# R7KA8T2AD register map
Vendor: Renesas Electronics Corporation; Series: RA8; File version: 1.10.02
CPU: CM85 r0p2, little endian, MPU, FPU, VTOR, 4 interrupt priority bits, 96 interrupts
Registers are 32-bit, read-write, reset 0x0 unless marked. A register's access mark holds for its fields unless they carry their own. Offsets are from the block's base; [hi:lo] are bit positions; {n}, {i} and the like mark numbered series; 'fields as' and 'values as' point back to an identical list.

## ESC — EtherCAT Slave Controller
Base 0x403A0000
0x00 TYPE 8-bit ro reset 0xA0
  [7:0] TYPE — Type of the EtherCAT slave controller
0x01 REVISION 8-bit ro reset 0x2
  [7:0] REV — Revision of the EtherCAT slave controller
0x02 BUILD 8-bit ro
  [7:0] BUILD — Build number of the EtherCAT slave controller
0x04 FMMU_NUM 8-bit ro reset 0x8 — FMMU Supported Register
  [7:0] NUMFMMU — Number of FMMU channels supported in the EtherCAT slave controller
0x05 SYNC_MANAGER 8-bit ro reset 0x8 — SyncManager Supported Register
  [7:0] NUMSYNC — Number of SyncManager channels supported in the EtherCAT slave controller
0x06 RAM_SIZE 8-bit ro reset 0x8
  [7:0] RAMSIZE — Process data RAM size supported in the EtherCAT slave controller (unit: KB)
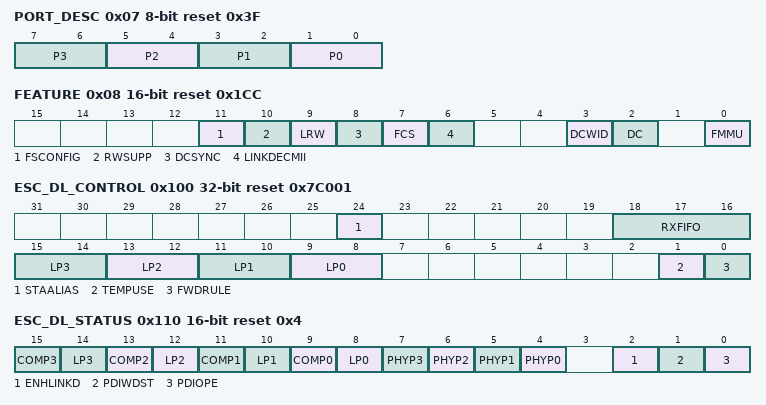
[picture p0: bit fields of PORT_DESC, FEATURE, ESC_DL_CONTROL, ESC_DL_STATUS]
0x07 PORT_DESC 8-bit ro reset 0x3F — Port Descriptor Register
  [all] fields
    0=Not implemented; 1=Not configured (SII EEPROM); 2=EBUS; 3=MII
  [2n+1:2n] P{n} (n=0..3) — Port {n} configuration
0x08 FEATURE 16-bit ro reset 0x1CC — ESC Features Supported Register
  [11] FSCONFIG — Fixed FMMU/SyncManager configuration
    0=Variable configuration; 1=Fixed configuration
  [10] RWSUPP — EtherCAT read/write command support (BRW, APRW, FPRW)
    0=Supported; 1=Not supported
  [9] LRW — EtherCAT LRW command support
    0=Supported; 1=Not supported
  [8] DCSYNC — Enhanced DC SYNC activation
    0=Not available; 1=Available
  [7] FCS — Separate handling of FCS errors
    0=Not supported; 1=Supported. Frames with wrong FCS and additional nibble will be counted separately in forwarded RX error counter.
  [6] LINKDECMII — Enhanced Link Detection in MII
    0=Not available; 1=Available
  [3] DCWID — Distributed Clock Width
    0=32 bits; 1=64 bits
  [2] DC — Distributed Clock
    0=Not available; 1=Available
  [0] FMMU — FMMU Operation
    0=Bit oriented; 1=Byte oriented
0x10 STATION_ADR 16-bit ro — Configured Station Address Register
  [15:0] NODADDR — Node Addressing Address Indication
0x12 STATION_ALIAS 16-bit — Configured Station Alias Register
  [15:0] NODALIADDR — Alias Address Indication
0x20 WR_REG_ENABLE 8-bit ro — Write Register Enable Register
  [0] ENABLE — Register Write Protection Unlock
0x21 WR_REG_PROTECT 8-bit ro — Write Register Protection Register
  [0] PROTECT — Register Write Protection Specification
    0=Protection disabled; 1=Protection enabled
0x30 ESC_WR_ENABLE 8-bit ro — ESC Write Enable Register
  [0] ENABLE — Register/Memory Write Protection Unlock
0x31 ESC_WR_PROTECT 8-bit ro — ESC Write Protection Register
  [0] PROTECT — Register/Memory Write Protection Specification
    0=Protection disabled; 1=Protection enabled
0x40 ESC_RESET_ECAT_R 8-bit ro — ESC Reset ECAT Register for read
  [1:0] RESET_ECAT — Reset Progress Status
    1=After writing 0x52; 2=After writing 0x45 (if 0x52 was written before); 0=Others
0x40 ESC_RESET_ECAT_W 8-bit ro (alternate view of ESC_RESET_ECAT_R) — ESC Reset ECAT Register for write
  [7:0] RESET_ECAT — Software Reset Setting
0x41 ESC_RESET_PDI_R 8-bit — ESC Reset PDI Register for read
  [1:0] RESET_PDI — Reset Progress Status
    values as ESC_RESET_ECAT_R.RESET_ECAT
0x41 ESC_RESET_PDI_W 8-bit (alternate view of ESC_RESET_PDI_R) — ESC Reset PDI Register for write
  [7:0] RESET_PDI — Software Reset Setting
0x100 ESC_DL_CONTROL ro reset 0x7C001
  [24] STAALIAS — Station Alias Status
    0=Ignore station alias; 1=Alias can be used for all configured address command types such as FPRD, FPWR
  [18:16] RXFIFO — RX FIFO Size
    0b00x=Shortened by 40 ns; 0b01x=Shortened by 40 ns; 6=No change; 7=Default; other=Others (No change)
  [2n+9:2n+8] LP{n} (n=0..3) — Loop Port {n} Configuration
    0=Auto; 1=Auto close; 2=Open; 3=Closed
  [1] TEMPUSE — Temporary Use of Bits 15 to 8 Settings
    0=Permanent use; 1=Use for about 1 second, then revert to previous settings
  [0] FWDRULE — Forwarding Rule
    0=EtherCAT frames are processed. Non-EtherCAT frames are forwarded without processing.; 1=EtherCAT frames are processed. Non-EtherCAT frames are destroyed.
0x108 PHYSICAL_RW_OFFSET 16-bit ro — Physical Read/Write Offset Register
  [15:0] RWOFFSET — Offset between Read and Write Addresses
0x110 ESC_DL_STATUS 16-bit ro reset 0x4
  [2n+9] COMP{n} (n=0..3) — Port {n} Communication State Indication
    0=No stable communication; 1=Communication established
  [2n+8] LP{n} (n=0..3) — Loop Port {n} State Indication
    0=Open; 1=Closed
  [n+4] PHYP{n} (n=0..3) — Port {n} Link State Indication
    0=No link; 1=Link detected
  [2] ENHLINKD — Enhanced Link Detection Indication
    0=Deactivated for all ports; 1=Activated for at least one port
  [1] PDIWDST — PDI Watchdog Timer Status
    0=Timeout of the watchdog timer; 1=Watchdog timer reloaded
  [0] PDIOPE — PDI/EEPROM Load State Indication
    0=EEPROM not loaded, the PDI not operational (process data RAM is not accessible); 1=EEPROM loaded correctly, the PDI operational (process data RAM is accessible)
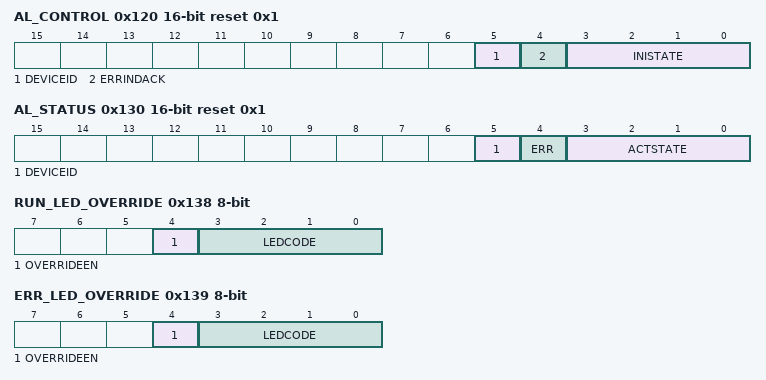
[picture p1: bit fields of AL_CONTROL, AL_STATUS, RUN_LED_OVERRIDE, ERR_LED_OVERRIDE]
0x120 AL_CONTROL 16-bit ro reset 0x1
  [5] DEVICEID — Device ID Request
    0=No request is present; 1=A request is present
  [4] ERRINDACK — Error Indication Acknowledge (Response)
    0=Error Indication in AL status register is not acknowledged; 1=Error Indication in AL status register is acknowledged
  [3:0] INISTATE — Change the state transition of the device state machine.
    1=Initial state request; 2=Pre-operational state request; 3=Bootstrap state request; 4=Safe-operational state request; 8=Operational state request; other=Others (Reserved)
0x130 AL_STATUS 16-bit reset 0x1
  [5] DEVICEID — Device ID Load State Indication
    0=Loading failed; 1=Loading was successful
  [4] ERR — Error State Indication
    0=The device is in the state as requested or flag was cleared by command; 1=The device has not entered the requested state or the state was changed as a result of local action
  [3:0] ACTSTATE — State Machine State Indication
    1=Initial state; 2=Pre-operational state; 3=Request bootstrap state; 4=Safe-operational state; 8=Operational state
0x134 AL_STATUS_CODE 16-bit
  [15:0] STATUSCODE — AL status code
0x138 RUN_LED_OVERRIDE 8-bit
  [4] OVERRIDEEN — Override Setting
    0=Override disabled; 1=Override enabled
  [3:0] LEDCODE — LED Code Indication (FSM state: Bits [3:0] of the AL Status register, AL_STATUS)
    0=Off (FSM: 1-Init); 13=Blinking (FSM: 2-PreOp); 14=Flickering (FSM: 3-Bootstrap); 15=On (FSM: 8-Op); other=Others (Flash 1x - 12x (FSM: 4-SafeOp 1x))
0x139 ERR_LED_OVERRIDE 8-bit
  [4] OVERRIDEEN — Override Setting
    0=Override disabled; 1=Override enabled
  [3:0] LEDCODE — LED Code Indication
    0=Off; 13=Blinking; 14=Flickering; 15=On; other=Others (Flash 1x to 12x)
0x140 PDI_CONTROL 8-bit ro reset 0x80
  [7:0] PDI — Process Data Interface. In this LSI, the following value is indicated.
    128=On-chip bus
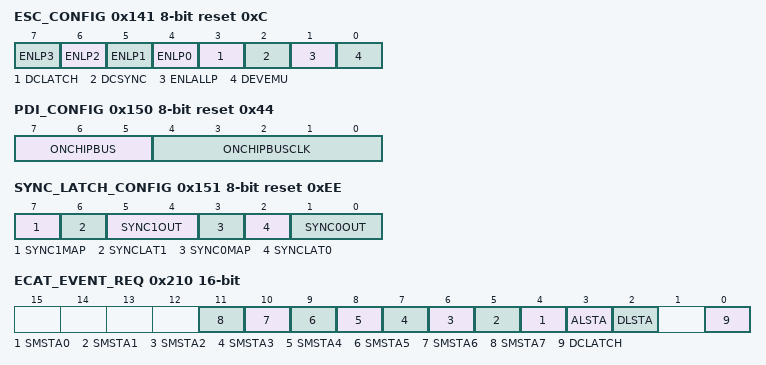
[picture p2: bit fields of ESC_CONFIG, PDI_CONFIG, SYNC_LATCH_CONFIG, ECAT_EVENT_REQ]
0x141 ESC_CONFIG 8-bit ro reset 0xC — ESC Configuration Register
  [n+4] ENLP{n} (n=0..3) — Port {n} Enhanced Link Detection Setting
    0=Disabled (if bit 9 of address 0 in the EEPROM = 0); 1=Enabled
  [3] DCLATCH — Sets the latch input unit for distributed clocks
    0=Disabled (power saving); 1=Enabled
  [2] DCSYNC — Sets the SYNC output unit for distributed clocks (fixed to 1 in this LSI)
    0=Disabled (power saving); 1=Enabled
  [1] ENLALLP — Sets enhanced link detection for all ports
    0=Disabled (if bits 15 to 12 of address 0 in the EEPROM = 0); 1=Enabled at all ports
  [0] DEVEMU — Device emulation (control of AL status)
    0=The AL status register must be set by the PDI; 1=The AL status register is set to a value written to the AL control register
0x150 PDI_CONFIG 8-bit ro reset 0x44 — PDI Configuration Register
  [7:5] ONCHIPBUS — On-Chip Bus Type Indication
  [4:0] ONCHIPBUSCLK — On-Chip Bus Clock Indication
0x151 SYNC_LATCH_CONFIG 8-bit ro reset 0xEE — SYNC/LATCH PDI Configuration Register
  [7] SYNC1MAP — SYNC1 State Mapping Indication
    0=Disabled; 1=Enabled
  [6] SYNCLAT1 — SYNC1/LATCH1 Indication
    0=LATCH1 input; 1=SYNC1 output
  [5:4] SYNC1OUT — SYNC1 Output Driver and Polarity Indication
  [3] SYNC0MAP — SYNC0 State Mapping Indication
    0=Disabled; 1=Enabled
  [2] SYNCLAT0 — SYNC0/LATCH0 Indication
    0=LATCH0 input; 1=SYNC0 output
  [1:0] SYNC0OUT — SYNC0 Output Driver and Polarity Indication
0x152 EXT_PDI_CONFIG 16-bit ro — Extended PDI Configuration Register
  [1:0] DATABUSWID — PDI Data Bus Width Indication
    0=4 bytes; 1=1 byte; 2=2 bytes
0x200 ECAT_EVENT_MASK 16-bit ro
  [15:0] ECATEVMASK — Event Request Mask Setting
    0=The corresponding bit of the ECAT Event Request register (ECAT_EVENT_REQ at 0x0210) is not mapped; 1=The corresponding bit of the ECAT Event Request register is mapped
0x204 AL_EVENT_MASK reset 0xFFFF0F
  [31:0] ALEVMASK — Event Request Mask Setting
    0=The corresponding bit of the AL Event Request register (AL_EVENT_REQ at 0x0220) is not mapped; 1=The corresponding bit of the AL Event Request register is mapped
0x210 ECAT_EVENT_REQ 16-bit ro — ECAT Event Request Register
  [n+4] SMSTA{n} (n=0..7) — Mirror value of SyncManager {n} Status Indication
    0=No Sync channel {n} event; 1=Sync channel {n} event pending
  [3] ALSTA — AL Status Event State Indication
    0=No change in AL status; 1=AL status change
  [2] DLSTA — DL Status Event State Indication
    0=No change in DL status; 1=DL status change
  [0] DCLATCH — DC Latch Event State Indication
    0=No change on DC latch inputs; 1=At least one change on DC latch inputs
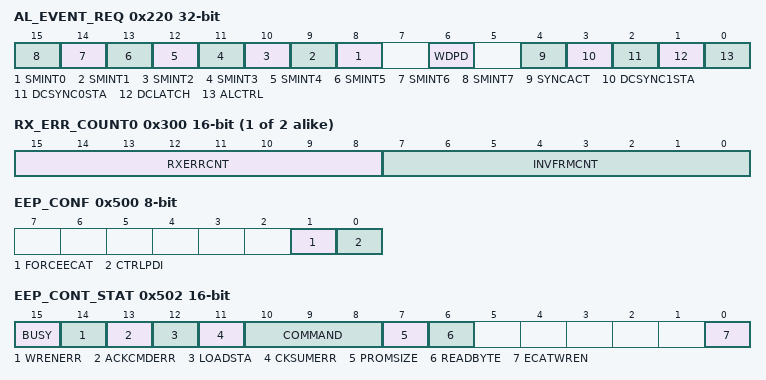
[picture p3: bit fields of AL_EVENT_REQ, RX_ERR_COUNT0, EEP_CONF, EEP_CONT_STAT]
0x220 AL_EVENT_REQ ro — AL Event Request Register
  [n+8] SMINT{n} (n=0..7) — SyncManager {n} interrupt (bit 0 or 1 of the SyncManager status register ({0x805+8n}))
    0=No SyncManager {n} interrupt; 1=SyncManager {n} interrupt pending
  [6] WDPD — Watchdog Process Data Indication
    0=Valid; 1=Timeout
  [4] SYNCACT — SyncManager Activation Indication
    0=No change in any SyncManager; 1=At least one SyncManager changed
  [3] DCSYNC1STA — DC SYNC1 State Indication
  [2] DCSYNC0STA — DC SYNC0 State Indication
  [1] DCLATCH — DC Latch Event State Indication
    values as ECAT_EVENT_REQ.DCLATCH
  [0] ALCTRL — AL Control Event State Indication
    0=No change in the AL control register; 1=The AL control register has been written
{0x300+2i} RX_ERR_COUNT{i} (i=0..1) 16-bit ro — RX Error Counter {i} Register (n = 0 to 1)
  [15:8] RXERRCNT — RX Frame Error Counter Value Indication
  [7:0] INVFRMCNT — Invalid Frame Counter Value Indication
{0x308+i} FWD_RX_ERR_COUNT{i} (i=0..1) 8-bit ro — Forwarded RX Error Counter {i} Register (n = 0 to 1)
  [7:0] FWDERRCNT — Forwarded Error Counter Value Indication
0x30C ECAT_PROC_ERR_COUNT 8-bit ro — ECAT Processing Unit Error Counter Register
  [7:0] EPUERRCNT — Processing Unit Error Counter Value Indication
0x30D PDI_ERR_COUNT 8-bit ro — PDI Error Counter Register
  [7:0] PDIERRCNT — PDI Error Counter Value Indication
{0x310+i} LOST_LINK_COUNT{i} (i=0..1) 8-bit ro — Lost Link Counter {i} Register (n = 0 to 1)
  [7:0] LOSTLINKCNT — Lost Link Counter Value Indication
0x400 WD_DIVIDE 16-bit ro reset 0x9C2 — Watchdog Divider Register
  [15:0] WDDIV — Watchdog Clock Frequency Divisor Setting
0x410 WDT_PDI 16-bit ro reset 0x3E8 — Watchdog Time PDI Register
  [15:0] WDTIMPDI — Watchdog Overflow Time Setting
0x420 WDT_DATA 16-bit ro reset 0x3E8 — Watchdog Time Process Data Register
  [15:0] WDTIMPD — Watchdog Overflow Time Setting
0x440 WDS_DATA 16-bit ro — Watchdog Status Process Data Register
  [0] WDSTAPD — Watchdog State Indication
    0=The timeout period of the process data watchdog timer elapses; 1=The process data watchdog timer is active or disabled
0x442 WDC_DATA 8-bit ro — Watchdog Counter Process Data Register
  [7:0] WDCNTPD — Watchdog Counter Value Indication
0x443 WDC_PDI 8-bit ro — Watchdog Counter PDI Register
  [7:0] WDCNTPDI — Watchdog Counter Value Indication
0x500 EEP_CONF 8-bit ro — EEPROM Configuration Register
  [1] FORCEECAT — EEPROM Access Right Change
    0=No change; 1=Reset bit 0 of the EEPROM PDI Access State register (EEP_STATE at 0x0501) to 0. That is, prohibit access to the EEPROM by the PDI.
  [0] CTRLPDI — PDI EEPROM Control
    0=The PDI has no EEPROM control; 1=The PDI has EEPROM control
0x501 EEP_STATE 8-bit — EEPROM PDI Access State Register
  [0] PDIACCESS — EEPROM Access Right Setting
    0=Prohibits the PDI from access to the EEPROM; 1=The PDI has access to the EEPROM
0x502 EEP_CONT_STAT 16-bit (reset mask 0xFF41) — EEPROM Control/Status Register
  [15] BUSY ro — EEPROM Interface State Indication
    0=The EEPROM interface is idle; 1=The EEPROM interface is busy
  [14] WRENERR ro — Write Enable Error Indication
    0=No error; 1=Write command without write enable
  [13] ACKCMDERR ro — Acknowledge/Command Error Indication
    0=No error; 1=Missing EEPROM acknowledge or invalid command
  [12] LOADSTA ro — EEPROM Loading Status Indication
    0=EEPROM has been loaded and device information has no problem; 1=EEPROM has not been loaded and device information is not available (EEPROM loading in progress or finished with a failure)
  [11] CKSUMERR ro — Checksum Error Indication
    0=No error in the checksum; 1=Error in the checksum
  [10:8] COMMAND
    0=No command/EEPROM idle (clear error bits); 1=Read; 2=Write; 4=Reload; other=Others (Reserved/invalid commands (must not be issued))
  [7] PROMSIZE ro — EEPROM Algorithm Indication
    0=1 address byte (1-Kbit to 16-Kbit EEPROMs); 1=2 address bytes (32-Kbit to 4-Mbit EEPROMs)
  [6] READBYTE ro — EEPROM Read Byte Indication
    0=4 bytes; 1=8 bytes
  [0] ECATWREN ro — ECAT Write Enable
    0=Write requests are disabled; 1=Write requests are enabled
0x504 EEP_ADR — EEPROM Address Register
  [31:0] ADDRESS — EEPROM Address Setting
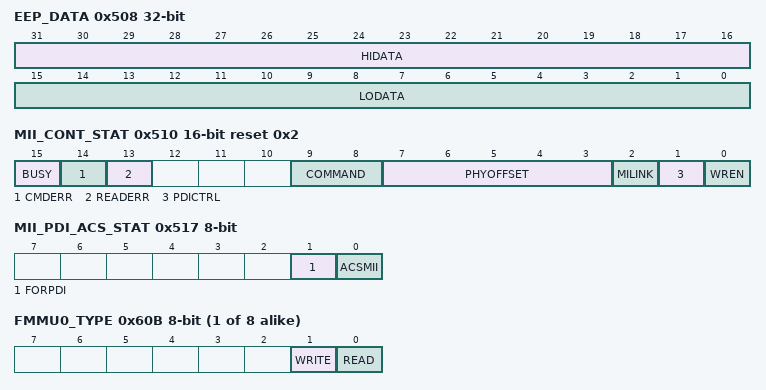
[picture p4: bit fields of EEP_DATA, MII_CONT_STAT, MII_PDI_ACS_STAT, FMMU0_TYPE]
0x508 EEP_DATA — EEPROM Data Register
  [31:16] HIDATA ro — Data read from the EEPROM (upper 2 bytes)
  [15:0] LODATA — Data to be written to the EEPROM or data read from the EEPROM (lower 2 bytes)
0x510 MII_CONT_STAT 16-bit reset 0x2 — MII Management Control/Status Register
  [15] BUSY ro — MII Management State Indication
    0=MII management interface is idle; 1=MII management interface is busy
  [14] CMDERR ro — Command Error Indication
    0=Last command was successful; 1=Invalid command or write command without write enable
  [13] READERR — Read Error Indication
    0=No read error; 1=Read error occurred (PHY or register not available)
  [9:8] COMMAND
    0=No command/MI idle (clear error bits); 1=Read; 2=Write; other=Others (Setting prohibited)
  [7:3] PHYOFFSET ro — PHY Address Offset Indication
  [2] MILINK ro — MI Link Detection
    0=Not available; 1=Available
  [1] PDICTRL ro — PDI Control Indication
    0=Only ECAT control; 1=PDI control possible
  [0] WREN ro — Write Enable
    0=Disabled; 1=Enabled
0x512 PHY_ADR 8-bit — PHY Address Register
  [4:0] PHYADDR — PHY Address Setting
0x513 PHY_REG_ADR 8-bit — PHY Register Address Register
  [4:0] PHYREGADDR — Address of PHY register
0x514 PHY_DATA 16-bit
  [15:0] PHYREGDATA — PHY Register Data Indication/Setting
0x516 MII_ECAT_ACS_STAT 8-bit ro — MII Management ECAT Access State Register
  [0] ACSMII — MII Management Interface Access Right Setting
    0=Enables access to the MII management interface by the PDI; 1=Exclusive access to the MII management interface by the ECAT
0x517 MII_PDI_ACS_STAT 8-bit — MII Management PDI Access State Register
  [1] FORPDI ro — Forced change of access by the PDI (forced change of bit 0)
    0=The value of bit 0 of this register is not changed; 1=The value of bit 0 of this register is reset to 0 (the right of access is changed to the ECAT)
  [0] ACSMII — Right of access to the MII management interface
    0=Access to the MII management interface by the ECAT; 1=Access to the MII management interface by the PDI
{0x600+0x10*i} FMMU{i}_L_START_ADR (i=0..7) ro — FMMU Logical Start Address {i} Register (n = 0 to 7)
  [31:0] LSTAADR — Logical Start Address Setting
{0x604+0x10*i} FMMU{i}_LEN (i=0..7) 16-bit ro — FMMU Length {i} Register (n = 0 to 7)
  [15:0] FMMULEN — Area Size Specification
{0x606+0x10*i} FMMU{i}_L_START_BIT (i=0..7) 8-bit ro — FMMU Logical Start Bit {i} Register (n = 0 to 7)
  [2:0] LSTABIT — Start Bit Setting
{0x607+0x10*i} FMMU{i}_L_STOP_BIT (i=0..7) 8-bit ro — FMMU Logical Stop Bit {i} Register (n = 0 to 7)
  [2:0] LSTPBIT — Last Bit Setting
{0x608+0x10*i} FMMU{i}_P_START_ADR (i=0..7) 16-bit ro — FMMU Physical Start Address {i} Register (n = 0 to 7)
  [15:0] PHYSTAADR — Physical Start Address Setting
{0x60A+0x10*i} FMMU{i}_P_START_BIT (i=0..7) 8-bit ro — FMMU Physical Start Bit {i} Register (n = 0 to 7)
  [2:0] PHYSTABIT — Physical Start Bit Setting
{0x60B+0x10*i} FMMU{i}_TYPE (i=0..7) 8-bit ro — FMMU Type {i} Register (n = 0 to 7)
  [1] WRITE — Write Access Mapping Setting
    0=Disabled; 1=Enabled
  [0] READ — Read Access Mapping Setting
    0=Disabled; 1=Enabled
{0x60C+0x10*i} FMMU{i}_ACT (i=0..7) 8-bit ro — FMMU Activate {i} Register (n = 0 to 7)
  [0] ACTIVATE — FMMU Enable/Disable
    0=Disabled; 1=Enabled
{0x800+8i} SM{i}_P_START_ADR (i=0..7) 16-bit ro — SyncManager Physical Start Address {i} Register (n = 0 to 7)
  [15:0] SMSTAADDR — Physical Start Address Setting
{0x802+8i} SM{i}_LEN (i=0..7) 16-bit ro — SyncManager Length {i} Register (n = 0 to 7)
  [15:0] SMLEN — Area Size Setting
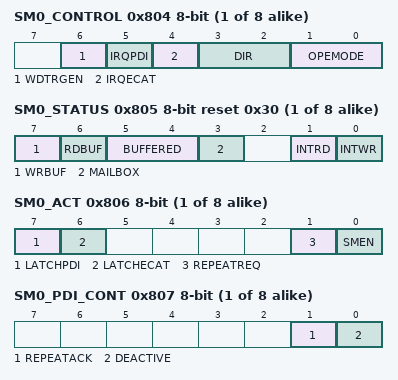
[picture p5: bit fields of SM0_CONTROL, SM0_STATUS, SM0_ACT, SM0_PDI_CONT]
{0x804+8i} SM{i}_CONTROL (i=0..7) 8-bit ro — SyncManager Control {i} Register (n = 0 to 7)
  [6] WDTRGEN — Watchdog Trigger Setting
    0=Disabled; 1=Enabled
  [5] IRQPDI — AL Event Interrupt Setting
    0=Disabled; 1=Enabled
  [4] IRQECAT — ECAT Event Interrupt Setting
    0=Disabled; 1=Enabled
  [3:2] DIR — Transfer Direction Setting
    0=Read (ECAT: read access; PDI: write access); 1=Write (ECAT: write access; PDI: read access); other=Others (Reserved)
  [1:0] OPEMODE — Operating Mode Setting
    0=Buffer mode (3-buffer mode); 2=Mailbox mode (single buffer mode); other=Others (Reserved)
{0x805+8i} SM{i}_STATUS (i=0..7) 8-bit ro reset 0x30 — SyncManager Status {i} Register (n = 0 to 7)
  [7] WRBUF — Write State Indication
  [6] RDBUF — Read State Indication
  [5:4] BUFFERED — Buffer Status Indication
    0=1st buffer; 1=2nd buffer; 2=3rd buffer; 3=No buffer written
  [3] MAILBOX — Mailbox Status Indication
    0=Mailbox empty; 1=Mailbox full
  [1] INTRD — Read Complete Interrupt State Indication
    0=Indicates that the buffer was successfully read; 1=Indicates that the first byte of the buffer was written (interrupt cleared)
  [0] INTWR — Write Complete Interrupt State Indication
    0=Indicates that the buffer was successfully written; 1=Indicates that the first byte of the buffer was read (interrupt cleared)
{0x806+8i} SM{i}_ACT (i=0..7) 8-bit ro — SyncManager Activate {i} Register (n = 0 to 7)
  [7] LATCHPDI — PDI Latch Event Specification
    0=No latch events; 1=Generates latch events if the PDI switches the buffers or accesses the buffer start address
  [6] LATCHECAT — ECAT Latch Event Specification
    0=No latch events; 1=Generates latch events if the EtherCAT master switches the buffers
  [1] REPEATREQ — Repeat Request
  [0] SMEN — SyncManager Enable/Disable
    0=Disabled. Memory is accessed without SyncManager control.; 1=Enabled. SyncManager is active and controls memory area set in configuration.
{0x807+8i} SM{i}_PDI_CONT (i=0..7) 8-bit — SyncManager PDI Control {i} Register (n = 0 to 7)
  [1] REPEATACK — Repeat Acknowledge
  [0] DEACTIVE — SyncManager Operation Indication/Setting
    0=Read: Normal operation. SyncManager is activated. Write: Activates SyncManager.; 1=Read: SyncManager is deactivated and reset. SyncManager locks access to memory area. Write: Deactivates SyncManager.
0x900 DC_RCV_TIME_PORT0 ro reset not defined — Receive Time Port 0 Register
  [31:0] RCVTIME0 — Receive Time Indication/Latch
0x904 DC_RCV_TIME_PORT1 ro reset not defined — Receive Time Port 1 Register
  [31:0] RCVTIME1 — Receive Time Indication
0x908 DC_RCV_TIME_PORT2 ro reset not defined — Receive Time Port 2 Register
  [31:0] RCVTIME2 — Receive Time Indication
0x910 DC_SYS_TIME_L ro — System Time Register L
  [31:0] SYSTIME — System Time Indication
0x914 DC_SYS_TIME_H ro — System Time Register H
  [31:0] SYSTIME — System Time Indication
0x918 DC_RCV_TIME_UNIT_L ro reset not defined — Receive Time ECAT Processing Unit Register L
  [31:0] RCVTIMEEPU — Receive Time Indication
0x91C DC_RCV_TIME_UNIT_H ro reset not defined — Receive Time ECAT Processing Unit Register H
  [31:0] RCVTIMEEPU — Receive Time Indication
0x920 DC_SYS_TIME_OFFSET_L ro — System Time Offset Register L
  [31:0] SYSTIMOFST — System Time and Local Time Difference Indication
0x924 DC_SYS_TIME_OFFSET_H ro — System Time Offset Register H
  [31:0] SYSTIMOFST — System Time and Local Time Difference Indication
0x928 DC_SYS_TIME_DELAY ro — System Time Delay Register
  [31:0] SYSTIMDLY — Propagation Delay Indication
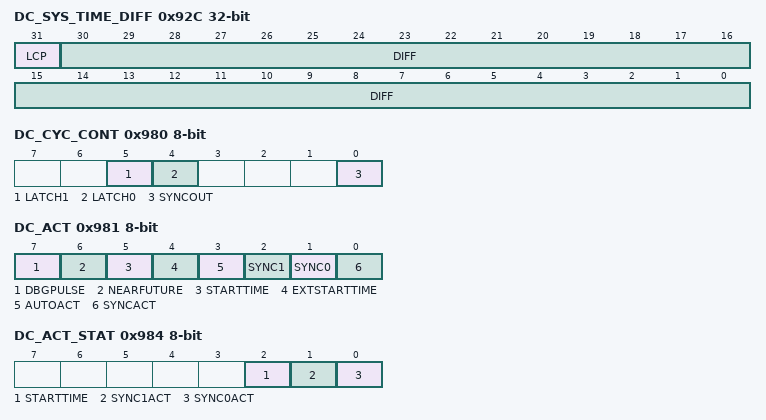
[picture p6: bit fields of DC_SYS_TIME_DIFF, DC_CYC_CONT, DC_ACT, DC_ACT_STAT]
0x92C DC_SYS_TIME_DIFF ro — System Time Difference Register
  [31] LCP — System Time Greater/Less Indication
    0=Local copy of the system time greater than or equal to the received system time; 1=Local copy of the system time less than the received system time
  [30:0] DIFF — System Time Mean Difference Indication
0x930 DC_SPEED_COUNT_START 16-bit ro reset 0x1000 — Speed Counter Start Register
  [14:0] SPDCNTSTRT — Drift Correction Bandwidth Setting
0x932 DC_SPEED_COUNT_DIFF 16-bit ro — Speed Counter Difference Register
  [15:0] SPDCNTDIFF — Clock Period Deviation Indication
0x934 DC_SYS_TIME_DIFF_FIL_DEPTH 8-bit ro reset 0x4 — System Time Difference Filter Depth Register
  [3:0] SYSTIMDEP — Filter Depth Setting
0x935 DC_SPEED_COUNT_FIL_DEPTH 8-bit ro reset 0xC — Speed Counter Filter Depth Register
  [3:0] CLKPERDEP — Filter Depth Setting
0x980 DC_CYC_CONT 8-bit ro — Cyclic Unit Control Register
  [all] fields
    0=ECAT control; 1=PDI control
  [5] LATCH1 — Latch Input Unit 1 Control Setting
  [4] LATCH0 — Latch Input Unit 0 Control Setting
  [0] SYNCOUT — SYNC Output Unit Control Setting
0x981 DC_ACT 8-bit — Activation Register
  [7] DBGPULSE — Debug Pulse Setting
    0=Deactivated; 1=Immediately generates a single debug ping on the SYNC0 and SYNC1 pins in accord with the setting of bits 2 and 1 of this register
  [6] NEARFUTURE — Near Future Range Setting
    0=Up to 263 ns from now (1/2 of the DC width); 1=Up to 231 ns from now (about 2.1 sec.)
  [5] STARTTIME — Start Time Plausibility
    0=Disabled. Sync signal is generated if the start time is reached.; 1=Sync signal is generated immediately if the start time is outside the range of the near future
  [4] EXTSTARTTIME — Start Time Cyclic Operation Extension
    0=No extension; 1=Extends the start time written with 32 bits to 64 bits
  [3] AUTOACT — SYNC Output Unit Activation
    0=Deactivated; 1=Activated. Bit 0 is automatically set to 1 in this register after the start time is written.
  [2] SYNC1 — SYNC1 Output Setting
    0=Deactivated; 1=SYNC1 pulse output is generated
  [1] SYNC0 — SYNC0 Output Setting
    0=Deactivated; 1=SYNC0 pulse output is generated
  [0] SYNCACT — Sync Output Unit Activation
    0=Deactivated; 1=Activated
0x982 DC_PULSE_LEN 16-bit ro — SYNC Signal Pulse Length Register
  [15:0] PULSELEN — SYNC Signal Pulse Length Indication
    0=Acknowledge mode. In this mode, SYNC signal is cleared by reading the SYNC0 or SYNC1 status register (DC_SYNC0/1_STAT at 0x098E, 0x098F).
0x984 DC_ACT_STAT 8-bit ro — Activation Status Register
  [2] STARTTIME — Plausibility Result Indication
    0=The start time is within the near future; 1=The start time is out of the near future
  [1] SYNC1ACT — SYNC1 Status Indication
    0=First SYNC1 pulse is not pending; 1=First SYNC1 pulse is pending
  [0] SYNC0ACT — SYNC0 Status Indication
    0=First SYNC0 pulse is not pending; 1=First SYNC0 pulse is pending
0x98E DC_SYNC0_STAT 8-bit ro — SYNC0 Status Register
  [0] SYNC0STA — SYNC0 State Indication
0x98F DC_SYNC1_STAT 8-bit ro — SYNC1 Status Register
  [0] SYNC1STA — SYNC1 State Indication
0x990 DC_CYC_START_TIME_L — Start Time Cyclic Operation/Next SYNC0 Pulse Register L
  [31:0] STATIM — Start Time Setting/System Time Indication
0x994 DC_CYC_START_TIME_H — Start Time Cyclic Operation/Next SYNC0 Pulse Register H
  [31:0] STATIM — Start Time Setting/System Time Indication
0x998 DC_NEXT_SYNC1_PULSE_L ro — Next SYNC1 Pulse Register L
  [31:0] SYNC1PULSE — SYNC1 Pulse System Time Indication
0x99C DC_NEXT_SYNC1_PULSE_H ro — Next SYNC1 Pulse Register H
  [31:0] SYNC1PULSE — SYNC1 Pulse System Time Indication
0x9A0 DC_SYNC0_CYC_TIME — SYNC0 Cycle Time Register
  [31:0] SYNC0CYC — Time Between Consecutive SYNC0 Pulses
0x9A4 DC_SYNC1_CYC_TIME — SYNC1 Cycle Time Register
  [31:0] SYNC1CYC — Time between SYNC1 and SYNC0 Pulses
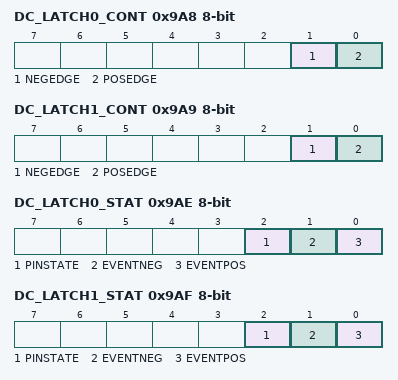
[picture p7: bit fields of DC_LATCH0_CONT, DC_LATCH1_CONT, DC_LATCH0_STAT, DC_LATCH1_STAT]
0x9A8 DC_LATCH0_CONT 8-bit — Latch 0 Control Register
  [1] NEGEDGE — Latch 0 Negative Edge Function Setting
    0=Continuous latch active; 1=Single event (only first event active)
  [0] POSEDGE — Latch 0 Positive Edge Function Setting
    values as NEGEDGE
0x9A9 DC_LATCH1_CONT 8-bit — Latch 1 Control Register
  [1] NEGEDGE — Latch 1 Negative Edge Function Setting
    0=Continuous Latch active; 1=Single event (only first event active)
  [0] POSEDGE — Latch 1 Positive Edge Function Setting
    values as DC_LATCH0_CONT.NEGEDGE
0x9AE DC_LATCH0_STAT 8-bit ro — Latch 0 Status Register
  [2] PINSTATE — Latch 0 Input Pin State Indication
  [1] EVENTNEG — Latch 0 Negative Edge Event Indication
    0=Falling edge not detected or continuous mode; 1=Falling edge detected and mode is single-event
  [0] EVENTPOS — Latch 0 Positive Edge Event Indication
    0=Rising edge not detected or continuous mode; 1=Rising edge detected and mode is single-event
0x9AF DC_LATCH1_STAT 8-bit ro — Latch 1 Status Register
  [2] PINSTATE — Latch 1 Input Pin State Indication
  [1] EVENTNEG — Latch 1 Negative Edge Event Indication
    values as DC_LATCH0_STAT.EVENTNEG
  [0] EVENTPOS — Latch 1 Positive Edge Event Indication
    values as DC_LATCH0_STAT.EVENTPOS
0x9B0 DC_LATCH0_TIME_POS_L ro — Latch 0 Time Positive Edge Register L
  [31:0] SYSTIME — System Time Indication
0x9B4 DC_LATCH0_TIME_POS_H ro — Latch 0 Time Positive Edge Register H
  [31:0] SYSTIME — System Time Indication
0x9B8 DC_LATCH0_TIME_NEG_L ro — Latch 0 Time Negative Edge Register L
  [31:0] SYSTIME — System Time Indication
0x9BC DC_LATCH0_TIME_NEG_H ro — Latch 0 Time Negative Edge Register H
  [31:0] SYSTIME — System Time Indication
0x9C0 DC_LATCH1_TIME_POS_L ro — Latch 1 Time Positive Edge Register L
  [31:0] SYSTIME — System Time Indication
0x9C4 DC_LATCH1_TIME_POS_H ro — Latch 1 Time Positive Edge Register H
  [31:0] SYSTIME — System Time Indication
0x9C8 DC_LATCH1_TIME_NEG_L ro — Latch 1 Time Negative Edge Register L
  [31:0] SYSTIME — System Time Indication
0x9CC DC_LATCH1_TIME_NEG_H ro — Latch 1 Time Negative Edge Register H
  [31:0] SYSTIME — System Time Indication
0x9F0 DC_ECAT_CNG_EV_TIME ro — Buffer Change Event Time Register
  [31:0] ECATCHANGE — Local Time Indication
0x9F8 DC_PDI_START_EV_TIME ro — PDI Buffer Start Event Time Register
  [31:0] PDISTART — Local Time Indication
0x9FC DC_PDI_CNG_EV_TIME ro — PDI Buffer Change Event Time Register
  [31:0] PDICHANGE — Local Time Indication
0xE00 PRODUCT_ID_L ro — Product ID Register L
  [31:0] PROID — Product ID Indication
0xE04 PRODUCT_ID_H ro — Product ID Register H
  [31:0] PROID — Product ID Indication
0xE08 VENDOR_ID_L ro — Vendor ID Register L
  [31:0] VENDORID — Vendor ID Indication

## ESC_NS — EtherCAT Slave Controller
Base 0x503A0000
Registers as ESC, without ESC_WR_ENABLE, ESC_WR_PROTECT, ESC_RESET_ECAT_R, ESC_RESET_ECAT_W, ESC_RESET_PDI_R, ESC_RESET_PDI_W, ESC_DL_CONTROL, ESC_DL_STATUS, ESC_CONFIG; these are added or differ:
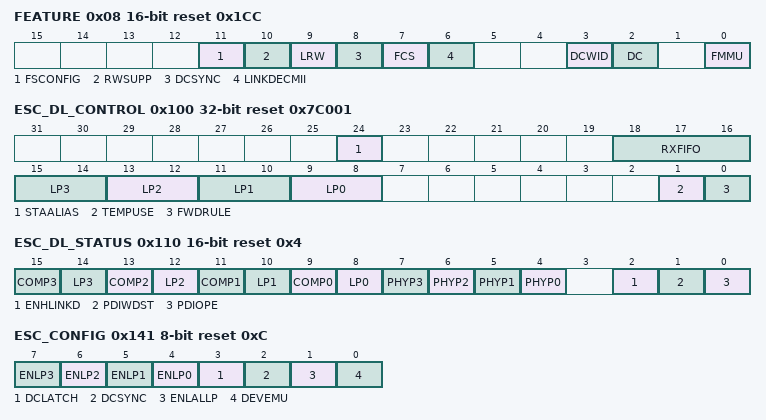
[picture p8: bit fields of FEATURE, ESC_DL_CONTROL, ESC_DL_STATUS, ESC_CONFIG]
0x08 FEATURE 16-bit ro reset 0x1CC — ESC Features Supported Register
  fields as ESC.FEATURE
0x30 ESC_WR_ENABLE 8-bit ro — ESC Write Enable Register
  [0] ENABLE — Register/Memory Write Protection Unlock
0x31 ESC_WR_PROTECT 8-bit ro — ESC Write Protection Register
  [0] PROTECT — Register/Memory Write Protection Specification
    0=Protection disabled; 1=Protection enabled
0x40 ESC_RESET_ECAT_R 8-bit ro — ESC Reset ECAT Register for read
  [1:0] RESET_ECAT — Reset Progress Status
    1=After writing 0x52; 2=After writing 0x45 (if 0x52 was written before); 0=Others
0x40 ESC_RESET_ECAT_W 8-bit ro (alternate view of ESC_RESET_ECAT_R) — ESC Reset ECAT Register for write
  [7:0] RESET_ECAT — Software Reset Setting
0x41 ESC_RESET_PDI_R 8-bit — ESC Reset PDI Register for read
  [1:0] RESET_PDI — Reset Progress Status
    values as ESC_RESET_ECAT_R.RESET_ECAT
0x41 ESC_RESET_PDI_W 8-bit (alternate view of ESC_RESET_PDI_R) — ESC Reset PDI Register for write
  [7:0] RESET_PDI — Software Reset Setting
0x100 ESC_DL_CONTROL ro reset 0x7C001
  fields as ESC.ESC_DL_CONTROL
0x110 ESC_DL_STATUS 16-bit ro reset 0x4
  fields as ESC.ESC_DL_STATUS
0x141 ESC_CONFIG 8-bit ro reset 0xC — ESC Configuration Register
  fields as ESC.ESC_CONFIG
